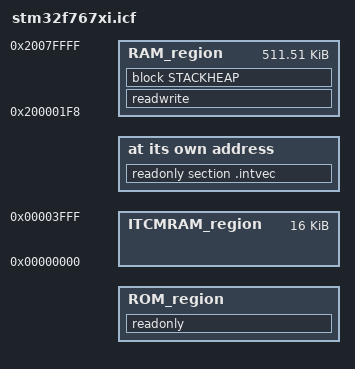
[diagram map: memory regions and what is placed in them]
if (!isdefinedsymbol(MBED_APP_START)) { define symbol MBED_APP_START = 0x08000000; }
if (!isdefinedsymbol(MBED_APP_SIZE)) { define symbol MBED_APP_SIZE = 0x200000; }

/* [ROM = 2048kb = 0x200000] */
define symbol __intvec_start__     = MBED_APP_START;
define symbol __region_ROM_start__ = MBED_APP_START;
define symbol __region_ROM_end__   = MBED_APP_START + MBED_APP_SIZE - 1;

/* [RAM = 512kb = 0x80000] Vector table dynamic copy: 126 vectors = 504 bytes (0x1F8) to be reserved in RAM */
define symbol __NVIC_start__          = 0x20000000;
define symbol __NVIC_end__            = 0x200001F7; /* Aligned on 8 bytes */
define symbol __region_RAM_start__    = 0x200001F8;
define symbol __region_RAM_end__      = 0x2007FFFF;

define symbol __region_ITCMRAM_start__ = 0x00000000;
define symbol __region_ITCMRAM_end__   = 0x00003FFF;

/* Memory regions */
define memory mem with size = 4G;
define region ROM_region = mem:[from __region_ROM_start__ to __region_ROM_end__];
define region RAM_region = mem:[from __region_RAM_start__ to __region_RAM_end__];
define region ITCMRAM_region = mem:[from __region_ITCMRAM_start__ to __region_ITCMRAM_end__];

/* Stack and Heap */
define symbol __size_cstack__ = 0x8000;
define symbol __size_heap__   = 0x10000;
define block CSTACK    with alignment = 8, size = __size_cstack__   { };
define block HEAP      with alignment = 8, size = __size_heap__     { };
define block STACKHEAP with fixed order { block HEAP, block CSTACK };

initialize by copy with packing = zeros { readwrite };
do not initialize  { section .noinit };

place at address mem:__intvec_start__ { readonly section .intvec };

place in ROM_region   { readonly };
place in RAM_region   { readwrite, block STACKHEAP };
